# MKL46Z4 register map
Vendor: Freescale Semiconductor, Inc.; File version: 1.6
CPU: CM0PLUS r0p0, little endian, no MPU, no FPU, 0x2 interrupt priority bits, 0x0 interrupts
Registers are 32-bit, read-write, reset 0x0 unless marked. A register's access mark holds for its fields unless they carry their own. Offsets are from the block's base; [hi:lo] are bit positions; {n}, {i} and the like mark numbered series; 'fields as' and 'values as' point back to an identical list.

## SIM — System Integration Module
Base 0x40047000; register names take the prefix SIM_
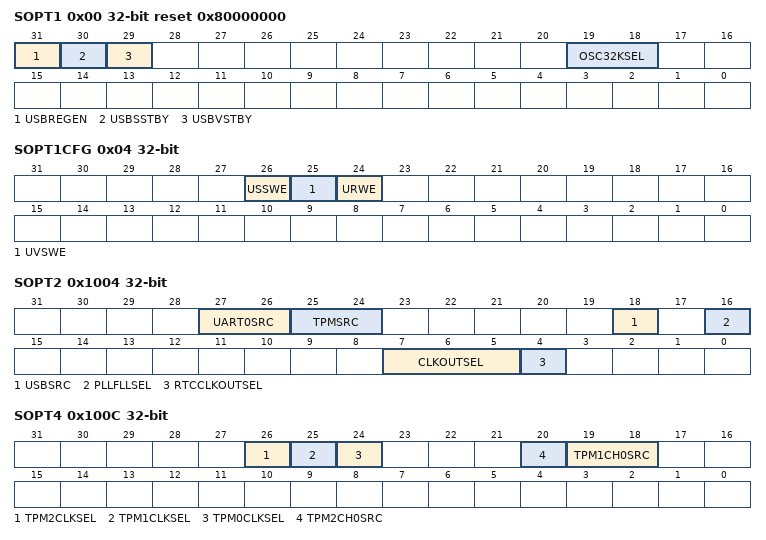
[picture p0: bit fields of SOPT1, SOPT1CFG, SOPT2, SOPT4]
0x00 SOPT1 reset 0x80000000 — System Options Register 1
  [31] USBREGEN — USB voltage regulator enable
    0=USB voltage regulator is disabled; 1=USB voltage regulator is enabled
  [30] USBSSTBY — USB voltage regulator in standby mode during Stop, VLPS, LLS and VLLS modes.
    0=USB voltage regulator not in standby during Stop, VLPS, LLS and VLLS modes; 1=USB voltage regulator in standby during Stop, VLPS, LLS and VLLS modes
  [29] USBVSTBY — USB voltage regulator in standby mode during VLPR and VLPW modes
    0=USB voltage regulator not in standby during VLPR and VLPW modes; 1=USB voltage regulator in standby during VLPR and VLPW modes
  [19:18] OSC32KSEL — 32K Oscillator Clock Select
    0=System oscillator (OSC32KCLK); 2=RTC_CLKIN; 3=LPO 1kHz
0x04 SOPT1CFG — SOPT1 Configuration Register
  [26] USSWE — USB voltage regulator stop standby write enable
    0=SOPT1 USBSSTB cannot be written; 1=SOPT1 USBSSTB can be written
  [25] UVSWE — USB voltage regulator VLP standby write enable
    0=SOPT1 USBVSTB cannot be written; 1=SOPT1 USBVSTB can be written
  [24] URWE — USB voltage regulator enable write enable
    0=SOPT1 USBREGEN cannot be written; 1=SOPT1 USBREGEN can be written
0x1004 SOPT2 — System Options Register 2
  [27:26] UART0SRC — UART0 Clock Source Select
    0=Clock disabled; 1=MCGFLLCLK clock , or MCGPLLCLK/2; 2=OSCERCLK clock; 3=MCGIRCLK clock
  [25:24] TPMSRC — TPM Clock Source Select
    values as UART0SRC
  [18] USBSRC — USB clock source select
    0=External bypass clock (USB_CLKIN); 1=MCGFLLCLK clock , or MCGPLLCLK/2 clock
  [16] PLLFLLSEL — PLL/FLL clock select
    0=MCGFLLCLK clock; 1=MCGPLLCLK clock with fixed divide by 2
  [7:5] CLKOUTSEL — CLKOUT select
    2=Bus clock; 3=LPO clock (1 kHz); 4=MCGIRCLK; 6=OSCERCLK
  [4] RTCCLKOUTSEL — RTC Clock Out Select
    0=RTC 1 Hz clock is output on the RTC_CLKOUT pin; 1=OSCERCLK clock is output on the RTC_CLKOUT pin
0x100C SOPT4 — System Options Register 4
  [26] TPM2CLKSEL — TPM2 External Clock Pin Select
    0=TPM2 external clock driven by TPM_CLKIN0 pin; 1=TPM2 external clock driven by TPM_CLKIN1 pin
  [25] TPM1CLKSEL — TPM1 External Clock Pin Select
    0=TPM1 external clock driven by TPM_CLKIN0 pin; 1=TPM1 external clock driven by TPM_CLKIN1 pin
  [24] TPM0CLKSEL — TPM0 External Clock Pin Select
    0=TPM0 external clock driven by TPM_CLKIN0 pin; 1=TPM0 external clock driven by TPM_CLKIN1 pin
  [20] TPM2CH0SRC — TPM2 Channel 0 Input Capture Source Select
    0=TPM2_CH0 signal; 1=CMP0 output
  [19:18] TPM1CH0SRC — TPM1 channel 0 input capture source select
    0=TPM1_CH0 signal; 1=CMP0 output; 3=USB start of frame pulse
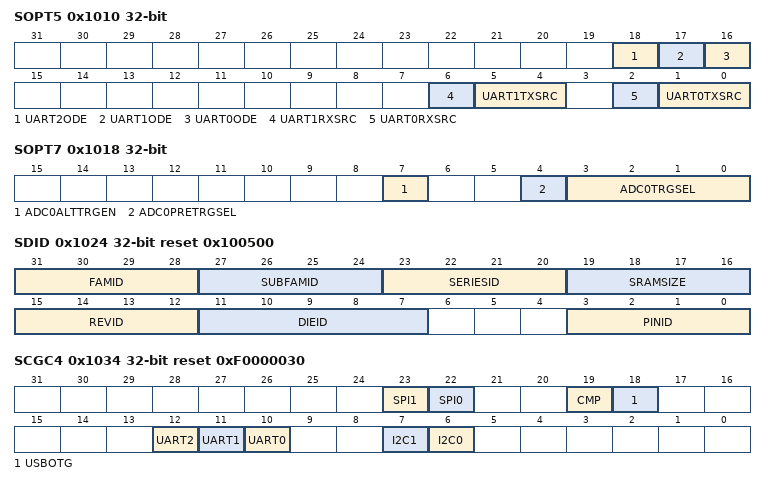
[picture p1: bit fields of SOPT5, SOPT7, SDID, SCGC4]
0x1010 SOPT5 — System Options Register 5
  [18] UART2ODE — UART2 Open Drain Enable
    0=Open drain is disabled on UART2; 1=Open drain is enabled on UART2
  [17] UART1ODE — UART1 Open Drain Enable
    0=Open drain is disabled on UART1; 1=Open drain is enabled on UART1
  [16] UART0ODE — UART0 Open Drain Enable
    0=Open drain is disabled on UART0; 1=Open drain is enabled on UART0
  [6] UART1RXSRC — UART1 Receive Data Source Select
    0=UART1_RX pin; 1=CMP0 output
  [5:4] UART1TXSRC — UART1 Transmit Data Source Select
    0=UART1_TX pin; 1=UART1_TX pin modulated with TPM1 channel 0 output; 2=UART1_TX pin modulated with TPM2 channel 0 output
  [2] UART0RXSRC — UART0 Receive Data Source Select
    0=UART_RX pin; 1=CMP0 output
  [1:0] UART0TXSRC — UART0 Transmit Data Source Select
    0=UART0_TX pin; 1=UART0_TX pin modulated with TPM1 channel 0 output; 2=UART0_TX pin modulated with TPM2 channel 0 output
0x1018 SOPT7 — System Options Register 7
  [7] ADC0ALTTRGEN — ADC0 Alternate Trigger Enable
    0=TPM1 channel 0 (A) and channel 1 (B) triggers selected for ADC0; 1=Alternate trigger selected for ADC0
  [4] ADC0PRETRGSEL — ADC0 Pretrigger Select
    0=Pre-trigger A; 1=Pre-trigger B
  [3:0] ADC0TRGSEL — ADC0 Trigger Select
    0=External trigger pin input (EXTRG_IN); 1=CMP0 output; 4=PIT trigger 0; 5=PIT trigger 1; 8=TPM0 overflow; 9=TPM1 overflow; 10=TPM2 overflow; 12=RTC alarm; 13=RTC seconds; 14=LPTMR0 trigger
0x1024 SDID ro reset 0x100500 — System Device Identification Register
  [31:28] FAMID — Kinetis family ID
    0=KL0x Family (low end); 1=KL1x Family (basic); 2=KL2x Family (USB); 3=KL3x Family (Segment LCD); 4=KL4x Family (USB and Segment LCD)
  [27:24] SUBFAMID — Kinetis Sub-Family ID
    {v}=KLx{v} Subfamily (v=2..7)
  [23:20] SERIESID — Kinetis Series ID
    1=KL family
  [19:16] SRAMSIZE — System SRAM Size
    0=0.5 KB; 1=1 KB; 2=2 KB; 3=4 KB; 4=8 KB; 5=16 KB; 6=32 KB; 7=64 KB
  [15:12] REVID — Device Revision Number
  [11:7] DIEID — Device Die Number
  [3:0] PINID — Pincount Identification
    0=16-pin; 1=24-pin; 2=32-pin; 3=36-pin; 4=48-pin; 5=64-pin; 6=80-pin; 8=100-pin; 11=Custom pinout (WLCSP)
0x1034 SCGC4 reset 0xF0000030 — System Clock Gating Control Register 4
  [all] fields
    0=Clock disabled; 1=Clock enabled
  [23] SPI1 — SPI1 Clock Gate Control
  [22] SPI0 — SPI0 Clock Gate Control
  [19] CMP — Comparator Clock Gate Control
  [18] USBOTG — USB Clock Gate Control
  [12] UART2 — UART2 Clock Gate Control
  [11] UART1 — UART1 Clock Gate Control
  [10] UART0 — UART0 Clock Gate Control
  [7] I2C1 — I2C1 Clock Gate Control
  [6] I2C0 — I2C0 Clock Gate Control
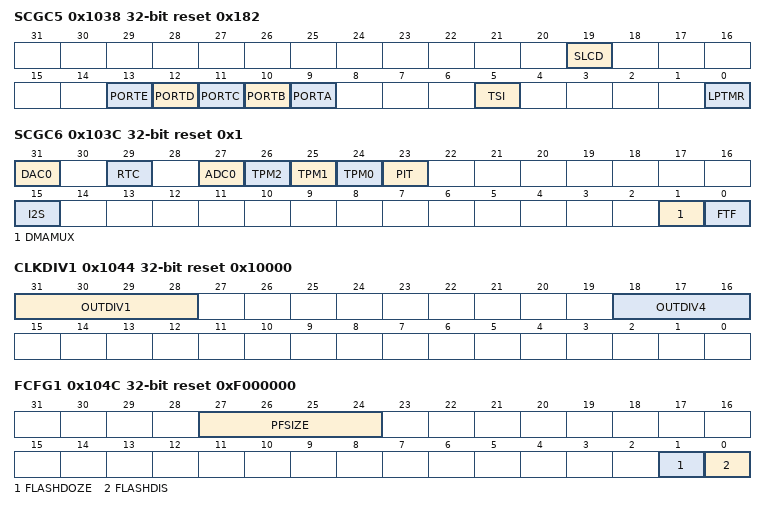
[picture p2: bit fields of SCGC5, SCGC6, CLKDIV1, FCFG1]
0x1038 SCGC5 reset 0x182 — System Clock Gating Control Register 5
  [19] SLCD — Segment LCD Clock Gate Control
    0=Clock disabled; 1=Clock enabled
  [13] PORTE — Port E Clock Gate Control
    0=Clock disabled; 1=Clock enabled
  [12] PORTD — Port D Clock Gate Control
    0=Clock disabled; 1=Clock enabled
  [11] PORTC — Port C Clock Gate Control
    0=Clock disabled; 1=Clock enabled
  [10] PORTB — Port B Clock Gate Control
    0=Clock disabled; 1=Clock enabled
  [9] PORTA — Port A Clock Gate Control
    0=Clock disabled; 1=Clock enabled
  [5] TSI — TSI Access Control
    0=Access disabled; 1=Access enabled
  [0] LPTMR — Low Power Timer Access Control
    0=Access disabled; 1=Access enabled
0x103C SCGC6 reset 0x1 — System Clock Gating Control Register 6
  [31] DAC0 — DAC0 Clock Gate Control
    0=Clock disabled; 1=Clock enabled
  [29] RTC — RTC Access Control
    0=Access and interrupts disabled; 1=Access and interrupts enabled
  [27] ADC0 — ADC0 Clock Gate Control
    0=Clock disabled; 1=Clock enabled
  [26] TPM2 — TPM2 Clock Gate Control
    0=Clock disabled; 1=Clock enabled
  [25] TPM1 — TPM1 Clock Gate Control
    0=Clock disabled; 1=Clock enabled
  [24] TPM0 — TPM0 Clock Gate Control
    0=Clock disabled; 1=Clock enabled
  [23] PIT — PIT Clock Gate Control
    0=Clock disabled; 1=Clock enabled
  [15] I2S — I2S Clock Gate Control
    0=Clock disabled; 1=Clock enabled
  [1] DMAMUX — DMA Mux Clock Gate Control
    0=Clock disabled; 1=Clock enabled
  [0] FTF — Flash Memory Clock Gate Control
    0=Clock disabled; 1=Clock enabled
0x1040 SCGC7 reset 0x100 — System Clock Gating Control Register 7
  [8] DMA — DMA Clock Gate Control
    0=Clock disabled; 1=Clock enabled
0x1044 CLKDIV1 reset 0x10000 — System Clock Divider Register 1
  [31:28] OUTDIV1 — Clock 1 Output Divider value
    {v}=Divide-by-{v+1} (v=0..15)
  [18:16] OUTDIV4 — Clock 4 Output Divider value
    {v}=Divide-by-{v+1} (v=0..7)
0x104C FCFG1 reset 0xF000000 — Flash Configuration Register 1
  [27:24] PFSIZE ro — Program Flash Size
    0=8 KB of program flash memory, 0.25 KB protection region; 1=16 KB of program flash memory, 0.5 KB protection region; 3=32 KB of program flash memory, 1 KB protection region; 5=64 KB of program flash memory, 2 KB protection region; 7=128 KB of program flash memory, 4 KB protection region; 9=256 KB of program flash memory, 8 KB protection region; 15=128 KB of program flash memory, 4 KB protection region 256 KB of program flash memory, 8 KB protection region
  [1] FLASHDOZE
    0=Flash remains enabled during Doze mode; 1=Flash is disabled for the duration of Doze mode
  [0] FLASHDIS — Flash Disable
    0=Flash is enabled; 1=Flash is disabled
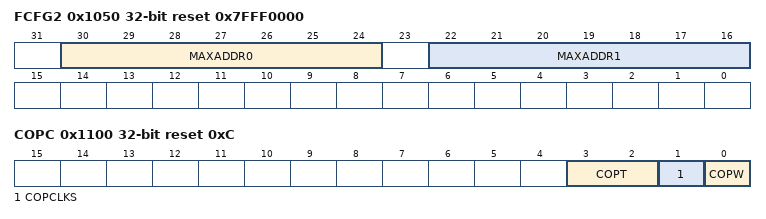
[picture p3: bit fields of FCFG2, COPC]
0x1050 FCFG2 ro reset 0x7FFF0000 — Flash Configuration Register 2
  [30:24] MAXADDR0 — Max Address lock
  [22:16] MAXADDR1 — This field concatenated with leading zeros plus the value of the MAXADDR1 field indicates the first invalid address of the second program flash block (flash block 1)
0x1058 UIDMH ro — Unique Identification Register Mid-High
  [15:0] UID — Unique Identification
0x105C UIDML ro — Unique Identification Register Mid Low
  [31:0] UID — Unique Identification
0x1060 UIDL ro — Unique Identification Register Low
  [31:0] UID — Unique Identification
0x1100 COPC reset 0xC — COP Control Register
  [3:2] COPT — COP Watchdog Timeout
    0=COP disabled; 1=COP timeout after 25 LPO cycles or 213 bus clock cycles; 2=COP timeout after 28 LPO cycles or 216 bus clock cycles; 3=COP timeout after 210 LPO cycles or 218 bus clock cycles
  [1] COPCLKS — COP Clock Select
    0=Internal 1 kHz clock is source to COP; 1=Bus clock is source to COP
  [0] COPW — COP Windowed Mode
    0=Normal mode; 1=Windowed mode
0x1104 SRVCOP wo — Service COP
  [7:0] SRVCOP — Service COP Register
